# WKUP_CTRL_MMR0_CFG0 register map
Vendor: Texas Instruments
Peripheral module from a debugger description file (folder am62A).
Registers are 32-bit, read-write, reset 0x0 unless marked. A register's access mark holds for its fields unless they carry their own. Offsets are as the file gives them; lines under a group give offsets from that group; [hi:lo] are bit positions; {n}, {i} and the like mark numbered series; 'fields as' and 'values as' point back to an identical list; <NAME> marks a mode.

## WKUP_CTRL_MMR0_CFG0 (part 1 of 2)
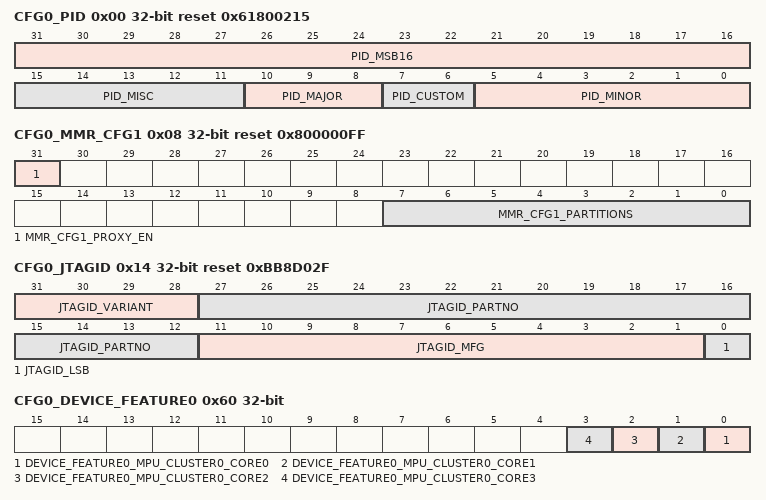
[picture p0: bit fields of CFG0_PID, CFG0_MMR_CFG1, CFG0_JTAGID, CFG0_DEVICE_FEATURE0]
0x00 CFG0_PID ro reset 0x61800215
  [31:16] PID_MSB16, [15:11] PID_MISC, [10:8] PID_MAJOR, [7:6] PID_CUSTOM, [5:0] PID_MINOR
0x08 CFG0_MMR_CFG1 ro reset 0x800000FF
  [31] MMR_CFG1_PROXY_EN — Proxy addressing activated
  [7:0] MMR_CFG1_PARTITIONS — Indicates present partitions
0x14 CFG0_JTAGID ro reset 0xBB8D02F
  [31:28] JTAGID_VARIANT — Used to indicate new PGs
  [27:12] JTAGID_PARTNO — Part number for boundary scan
  [11:1] JTAGID_MFG — Indicates manufacturer
  [0] JTAGID_LSB — Always 1
0x18 CFG0_JTAG_USER_ID ro
  [31:0] JTAG_USER_ID_USERCODE — Device information
0x30 CFG0_MAIN_DEVSTAT
  [15:0] MAIN_DEVSTAT_BOOTMODE — Specifies the device Primary and Backup boot media.
0x34 CFG0_MAIN_BOOTCFG ro
  [15:0] MAIN_BOOTCFG_BOOTMODE — Specifies the device Primary and Backup boot media as latched at PORz
0x44 CFG0_BOOT_PROGRESS
  [31:0] BOOT_PROGRESS_PROGRESS — Written by ROM to indicate boot progression. Values and their meaning are determined by the ROM.
0x60 CFG0_DEVICE_FEATURE0 ro
  [n] DEVICE_FEATURE0_MPU_CLUSTER0_CORE{n} (n=0..3) — MPU Cluster0 Core {n} is activated when set
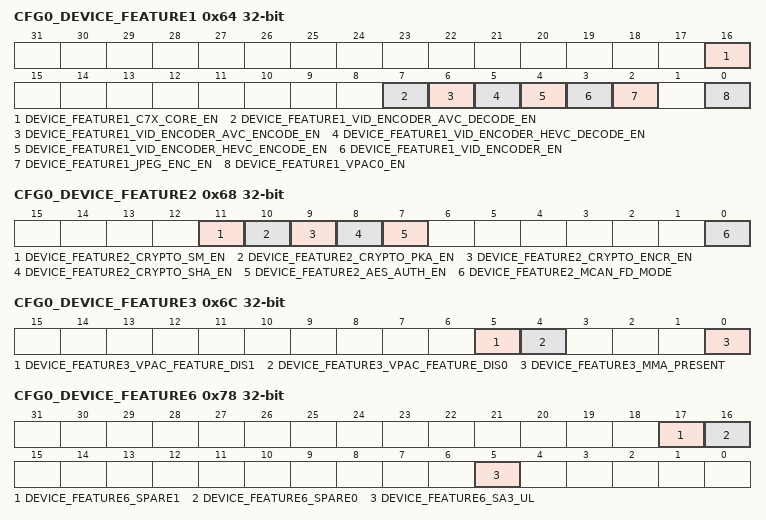
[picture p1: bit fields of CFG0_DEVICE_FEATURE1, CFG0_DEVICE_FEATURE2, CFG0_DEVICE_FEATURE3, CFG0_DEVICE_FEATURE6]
0x64 CFG0_DEVICE_FEATURE1 ro
  [16] DEVICE_FEATURE1_C7X_CORE_EN — C7x is activated when set
  [7] DEVICE_FEATURE1_VID_ENCODER_AVC_DECODE_EN — Video CODEC HEVC decode feature activated when set
  [6] DEVICE_FEATURE1_VID_ENCODER_AVC_ENCODE_EN — Video CODEC HEVC encode feature activated when set
  [5] DEVICE_FEATURE1_VID_ENCODER_HEVC_DECODE_EN — Video CODEC AVC decode feature activated when set
  [4] DEVICE_FEATURE1_VID_ENCODER_HEVC_ENCODE_EN — Video CODEC AVC encode feature activated when set
  [3] DEVICE_FEATURE1_VID_ENCODER_EN — Video CODEC is activated when set
  [2] DEVICE_FEATURE1_JPEG_ENC_EN — JPEG Encoder is activated when set
  [0] DEVICE_FEATURE1_VPAC0_EN — VPAC0 is activated when set
0x68 CFG0_DEVICE_FEATURE2 ro
  [11] DEVICE_FEATURE2_CRYPTO_SM_EN — SA3SS Crypto Module SM2, SM3, SM4 activated
  [10] DEVICE_FEATURE2_CRYPTO_PKA_EN — SA3SS Crypto Module PKA activated
  [9] DEVICE_FEATURE2_CRYPTO_ENCR_EN — SA3SS Crypto Module AES/3DES/DBRG activated
  [8] DEVICE_FEATURE2_CRYPTO_SHA_EN — SA3SS Crypto Module SHA/MD5 activated
  [7] DEVICE_FEATURE2_AES_AUTH_EN — AES authentication is activated in FlashSS and SMS when set
  [0] DEVICE_FEATURE2_MCAN_FD_MODE — FD mode is supported on all MCAN when set
0x6C CFG0_DEVICE_FEATURE3 ro
  [5] DEVICE_FEATURE3_VPAC_FEATURE_DIS1 — VPAC Feature 1 Deactivated When Set
  [4] DEVICE_FEATURE3_VPAC_FEATURE_DIS0 — VPAC Feature 0 DIsabled When Set
  [0] DEVICE_FEATURE3_MMA_PRESENT — C7x MMA Present when Set
0x78 CFG0_DEVICE_FEATURE6 ro
  [17] DEVICE_FEATURE6_SPARE1 — Spare1 LPSC is activated when set
  [16] DEVICE_FEATURE6_SPARE0 — Spare0 LPSC is activated when set
  [5] DEVICE_FEATURE6_SA3_UL — SA3SS domain security accelerator is activated when set
0x200 CFG0_MAC_ID0
  [31:0] MAC_ID0_MACID_LO — 32 lsbs of MAC address
0x204 CFG0_MAC_ID1
  [15:0] MAC_ID1_MACID_HI — 16 msbs of MAC address
0x220 CFG0_USB_DEVICE_ID0 reset 0x61650451
  [31:0] USB_DEVICE_ID0_ID0 — ROM writes 32-bit Value from Customer OTP to Here
0x224 CFG0_USB_DEVICE_ID1 reset 0x61650451
  [31:0] USB_DEVICE_ID1_ID1 — ROM writes 32-bit Value from Customer OTP to Here
{0x230+4i} CFG0_GP_SW{i} ro (i=0..2)
  [31:0] GP_SW{i}_VAL — general purpose value
0x23C CFG0_GP_SW3 ro
  [3:0] GP_SW3_VAL — general purpose value
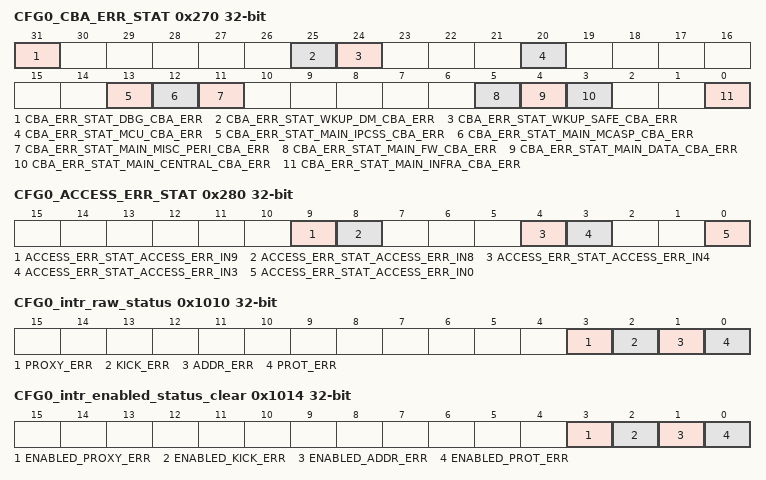
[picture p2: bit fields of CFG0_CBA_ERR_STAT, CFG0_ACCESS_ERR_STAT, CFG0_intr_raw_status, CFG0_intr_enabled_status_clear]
0x270 CFG0_CBA_ERR_STAT ro
  [31] CBA_ERR_STAT_DBG_CBA_ERR — Access Error from Main Debug CBASS
  [25] CBA_ERR_STAT_WKUP_DM_CBA_ERR — Access Error from Wkup Device Manager CBASS
  [24] CBA_ERR_STAT_WKUP_SAFE_CBA_ERR — Access Error from Wkup Safe CBASS
  [20] CBA_ERR_STAT_MCU_CBA_ERR — Access Error from MCU CBASS
  [13] CBA_ERR_STAT_MAIN_IPCSS_CBA_ERR — Access Error from Main IPCSS CBASS
  [12] CBA_ERR_STAT_MAIN_MCASP_CBA_ERR — Access Error from Main McASP CBASS
  [11] CBA_ERR_STAT_MAIN_MISC_PERI_CBA_ERR — Access Errror from Main Misc. Peripheral CBASS
  [5] CBA_ERR_STAT_MAIN_FW_CBA_ERR — Access Error from Main Firewall CBASS
  [4] CBA_ERR_STAT_MAIN_DATA_CBA_ERR — Access Error from Main Data CBASS
  [3] CBA_ERR_STAT_MAIN_CENTRAL_CBA_ERR — Access Error from Main Central CBASS
  [0] CBA_ERR_STAT_MAIN_INFRA_CBA_ERR — Access Error from Main Infrastructure CBASS
0x280 CFG0_ACCESS_ERR_STAT ro
  [9] ACCESS_ERR_STAT_ACCESS_ERR_IN9 — Access Error Detected in MCU PadCfg MMR
  [8] ACCESS_ERR_STAT_ACCESS_ERR_IN8 — Access Error Detected in MCU Ctrl MMR
  [4] ACCESS_ERR_STAT_ACCESS_ERR_IN4 — Access Error Detected in MAIN PadCfg MMR
  [3] ACCESS_ERR_STAT_ACCESS_ERR_IN3 — Access Error Detected in MAIN Ctrl MMR
  [0] ACCESS_ERR_STAT_ACCESS_ERR_IN0 — Access Error Detected in WKUP Ctrl MMR
{0x1008+0x4000*i} CFG0_LOCK{i}_KICK0 (i=0..7)
  [31:0] LOCK{i}_KICK0 — - KICK0 component
{0x100C+0x4000*i} CFG0_LOCK{i}_KICK1 (i=0..7)
  [31:0] LOCK{i}_KICK1 — - KICK1 component
0x1010 CFG0_intr_raw_status access not given
  [3] PROXY_ERR — Proxy0 access violation error. Raw status is read. Write a 1 to set the status. Writing a 0 has no effect. (access R/W1TS)
  [2] KICK_ERR — Kick access violation error. Raw status is read. Write a 1 to set the status. Writing a 0 has no effect. (access R/W1TS)
  [1] ADDR_ERR — Addressing violation error. Raw status is read. Write a 1 to set the status. Writing a 0 has no effect. (access R/W1TS)
  [0] PROT_ERR — Protection violation error. Raw status is read. Write a 1 to set the status. Writing a 0 has no effect. (access R/W1TS)
0x1014 CFG0_intr_enabled_status_clear access not given
  [3] ENABLED_PROXY_ERR — Proxy0 access violation error. Enabled status is read. Write a 1 to clear the status. Writing a 0 has no effect. (access R/W1TC)
  [2] ENABLED_KICK_ERR — Kick access violation error. Enabled status is read. Write a 1 to clear the status. Writing a 0 has no effect. (access R/W1TC)
  [1] ENABLED_ADDR_ERR — Addressing violation error. Enabled status is read. Write a 1 to clear the status. Writing a 0 has no effect. (access R/W1TC)
  [0] ENABLED_PROT_ERR — Protection violation error. Enabled status is read. Write a 1 to clear the status. Writing a 0 has no effect. (access R/W1TC)
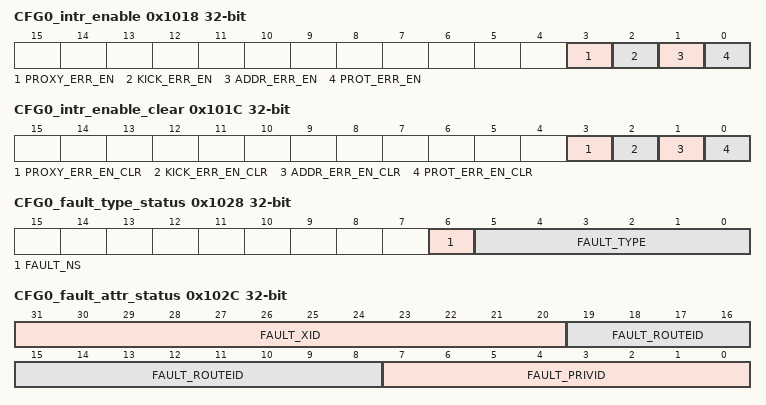
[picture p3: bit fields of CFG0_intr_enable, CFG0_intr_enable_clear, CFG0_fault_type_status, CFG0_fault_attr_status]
0x1018 CFG0_intr_enable access not given
  [3] PROXY_ERR_EN — Proxy0 access violation error enable. Write a 1 to set the enable. Writing a 0 has no effect. (access R/W1TS)
  [2] KICK_ERR_EN — Kick access violation error enable. Write a 1 to set the enable. Writing a 0 has no effect. (access R/W1TS)
  [1] ADDR_ERR_EN — Addressing violation error enable. Write a 1 to set the enable. Writing a 0 has no effect. (access R/W1TS)
  [0] PROT_ERR_EN — Protection violation error enable. Write a 1 to set the enable. Writing a 0 has no effect. (access R/W1TS)
0x101C CFG0_intr_enable_clear access not given
  [3] PROXY_ERR_EN_CLR — Proxy0 access violation error enable clear. Write a 1 to clear the enable. Writing a 0 has no effect. (access R/W1TC)
  [2] KICK_ERR_EN_CLR — Kick access violation error enable clear. Write a 1 to clear the enable. Writing a 0 has no effect. (access R/W1TC)
  [1] ADDR_ERR_EN_CLR — Addressing violation error enable clear. Write a 1 to clear the enable. Writing a 0 has no effect. (access R/W1TC)
  [0] PROT_ERR_EN_CLR — Protection violation error enable clear. Write a 1 to clear the enable. Writing a 0 has no effect. (access R/W1TC)
0x1020 CFG0_eoi
  [7:0] EOI_VECTOR — EOI vector value. Write this with interrupt distribution value in the chip.
0x1024 CFG0_fault_address ro
  [31:0] FAULT_ADDR — Fault Address.
0x1028 CFG0_fault_type_status ro
  [6] FAULT_NS — Non-secure access.
  [5:0] FAULT_TYPE — Fault Type 10_0000 = Supervisor read fault - priv = 1 dir = 1 dtype != 1 01_0000 = Supervisor write fault - priv = 1 dir = 0 00_1000 = Supervisor execute fault - priv = 1 dir = 1 dtype = 1 00_0100 = User read fault - priv = 0 dir = 1 dtype = 1 00_0010 = User write fault - priv = 0 dir = 0 00_0001 = User execute fault - priv = 0 dir = 1 dtype = 1 00_0000 = No fault
0x102C CFG0_fault_attr_status ro
  [31:20] FAULT_XID — XID.
  [19:8] FAULT_ROUTEID — Route ID.
  [7:0] FAULT_PRIVID — Privilege ID.
0x1030 CFG0_fault_clear wo
  [0] FAULT_CLR — Fault clear. Writing a 1 clears the current fault. Writing a 0 has no effect.
{0x1100+4i} CFG0_CLAIMREG_P0_R{i}_READONLY ro (i=0..6)
  [31:0] CLAIMREG_P0_R{i}_READONLY — Claim bits for Partition 0
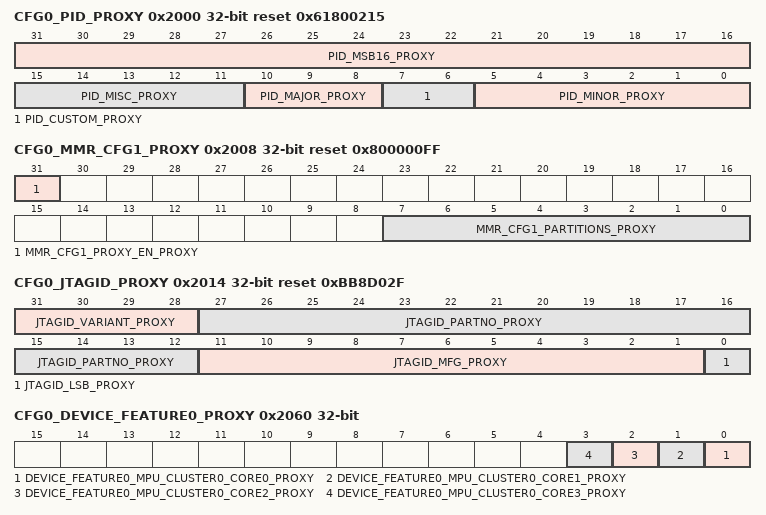
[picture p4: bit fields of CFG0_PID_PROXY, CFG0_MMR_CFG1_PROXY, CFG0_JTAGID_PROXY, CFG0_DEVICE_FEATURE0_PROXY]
0x2000 CFG0_PID_PROXY ro reset 0x61800215
  [31:16] PID_MSB16_PROXY, [15:11] PID_MISC_PROXY, [10:8] PID_MAJOR_PROXY, [7:6] PID_CUSTOM_PROXY, [5:0] PID_MINOR_PROXY
0x2008 CFG0_MMR_CFG1_PROXY ro reset 0x800000FF
  [31] MMR_CFG1_PROXY_EN_PROXY — Proxy addressing activated
  [7:0] MMR_CFG1_PARTITIONS_PROXY — Indicates present partitions
0x2014 CFG0_JTAGID_PROXY ro reset 0xBB8D02F
  [31:28] JTAGID_VARIANT_PROXY — Used to indicate new PGs
  [27:12] JTAGID_PARTNO_PROXY — Part number for boundary scan
  [11:1] JTAGID_MFG_PROXY — Indicates manufacturer
  [0] JTAGID_LSB_PROXY — Always 1
0x2018 CFG0_JTAG_USER_ID_PROXY ro
  [31:0] JTAG_USER_ID_USERCODE_PROXY — Device information
0x2030 CFG0_MAIN_DEVSTAT_PROXY
  [15:0] MAIN_DEVSTAT_BOOTMODE_PROXY — Specifies the device Primary and Backup boot media.
0x2034 CFG0_MAIN_BOOTCFG_PROXY ro
  [15:0] MAIN_BOOTCFG_BOOTMODE_PROXY — Specifies the device Primary and Backup boot media as latched at PORz
0x2044 CFG0_BOOT_PROGRESS_PROXY
  [31:0] BOOT_PROGRESS_PROGRESS_PROXY — Written by ROM to indicate boot progression. Values and their meaning are determined by the ROM.
0x2060 CFG0_DEVICE_FEATURE0_PROXY ro
  [n] DEVICE_FEATURE0_MPU_CLUSTER0_CORE{n}_PROXY (n=0..3) — MPU Cluster0 Core {n} is activated when set
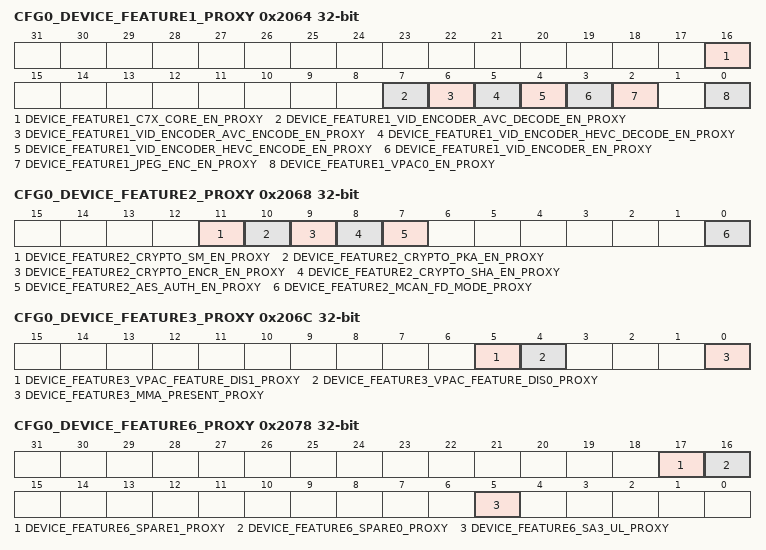
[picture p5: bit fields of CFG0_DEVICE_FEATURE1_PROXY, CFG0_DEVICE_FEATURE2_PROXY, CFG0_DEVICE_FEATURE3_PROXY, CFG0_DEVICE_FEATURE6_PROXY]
0x2064 CFG0_DEVICE_FEATURE1_PROXY ro
  [16] DEVICE_FEATURE1_C7X_CORE_EN_PROXY — C7x is activated when set
  [7] DEVICE_FEATURE1_VID_ENCODER_AVC_DECODE_EN_PROXY — Video CODEC HEVC decode feature activated when set
  [6] DEVICE_FEATURE1_VID_ENCODER_AVC_ENCODE_EN_PROXY — Video CODEC HEVC encode feature activated when set
  [5] DEVICE_FEATURE1_VID_ENCODER_HEVC_DECODE_EN_PROXY — Video CODEC AVC decode feature activated when set
  [4] DEVICE_FEATURE1_VID_ENCODER_HEVC_ENCODE_EN_PROXY — Video CODEC AVC encode feature activated when set
  [3] DEVICE_FEATURE1_VID_ENCODER_EN_PROXY — Video CODEC is activated when set
  [2] DEVICE_FEATURE1_JPEG_ENC_EN_PROXY — JPEG Encoder is activated when set
  [0] DEVICE_FEATURE1_VPAC0_EN_PROXY — VPAC0 is activated when set
0x2068 CFG0_DEVICE_FEATURE2_PROXY ro
  [11] DEVICE_FEATURE2_CRYPTO_SM_EN_PROXY — SA3SS Crypto Module SM2, SM3, SM4 activated
  [10] DEVICE_FEATURE2_CRYPTO_PKA_EN_PROXY — SA3SS Crypto Module PKA activated
  [9] DEVICE_FEATURE2_CRYPTO_ENCR_EN_PROXY — SA3SS Crypto Module AES/3DES/DBRG activated
  [8] DEVICE_FEATURE2_CRYPTO_SHA_EN_PROXY — SA3SS Crypto Module SHA/MD5 activated
  [7] DEVICE_FEATURE2_AES_AUTH_EN_PROXY — AES authentication is activated in FlashSS and SMS when set
  [0] DEVICE_FEATURE2_MCAN_FD_MODE_PROXY — FD mode is supported on all MCAN when set
0x206C CFG0_DEVICE_FEATURE3_PROXY ro
  [5] DEVICE_FEATURE3_VPAC_FEATURE_DIS1_PROXY — VPAC Feature 1 Deactivated When Set
  [4] DEVICE_FEATURE3_VPAC_FEATURE_DIS0_PROXY — VPAC Feature 0 DIsabled When Set
  [0] DEVICE_FEATURE3_MMA_PRESENT_PROXY — C7x MMA Present when Set
0x2078 CFG0_DEVICE_FEATURE6_PROXY ro
  [17] DEVICE_FEATURE6_SPARE1_PROXY — Spare1 LPSC is activated when set
  [16] DEVICE_FEATURE6_SPARE0_PROXY — Spare0 LPSC is activated when set
  [5] DEVICE_FEATURE6_SA3_UL_PROXY — SA3SS domain security accelerator is activated when set
0x2200 CFG0_MAC_ID0_PROXY
  [31:0] MAC_ID0_MACID_LO_PROXY — 32 lsbs of MAC address
0x2204 CFG0_MAC_ID1_PROXY
  [15:0] MAC_ID1_MACID_HI_PROXY — 16 msbs of MAC address
0x2220 CFG0_USB_DEVICE_ID0_PROXY reset 0x61650451
  [31:0] USB_DEVICE_ID0_ID0_PROXY — ROM writes 32-bit Value from Customer OTP to Here
0x2224 CFG0_USB_DEVICE_ID1_PROXY reset 0x61650451
  [31:0] USB_DEVICE_ID1_ID1_PROXY — ROM writes 32-bit Value from Customer OTP to Here
{0x2230+4i} CFG0_GP_SW{i}_PROXY ro (i=0..2)
  [31:0] GP_SW{i}_VAL_PROXY — general purpose value
0x223C CFG0_GP_SW3_PROXY ro
  [3:0] GP_SW3_VAL_PROXY — general purpose value
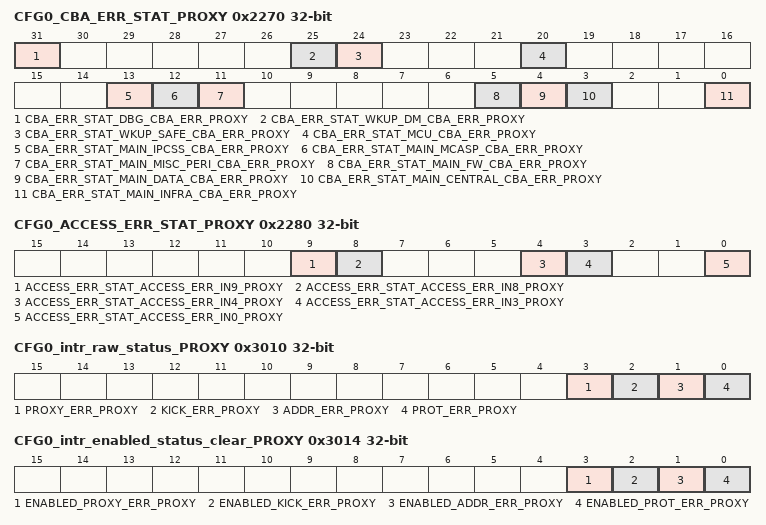
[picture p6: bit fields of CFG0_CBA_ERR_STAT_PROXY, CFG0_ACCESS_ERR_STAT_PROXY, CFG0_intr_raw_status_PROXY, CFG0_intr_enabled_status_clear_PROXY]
0x2270 CFG0_CBA_ERR_STAT_PROXY ro
  [31] CBA_ERR_STAT_DBG_CBA_ERR_PROXY — Access Error from Main Debug CBASS
  [25] CBA_ERR_STAT_WKUP_DM_CBA_ERR_PROXY — Access Error from Wkup Device Manager CBASS
  [24] CBA_ERR_STAT_WKUP_SAFE_CBA_ERR_PROXY — Access Error from Wkup Safe CBASS
  [20] CBA_ERR_STAT_MCU_CBA_ERR_PROXY — Access Error from MCU CBASS
  [13] CBA_ERR_STAT_MAIN_IPCSS_CBA_ERR_PROXY — Access Error from Main IPCSS CBASS
  [12] CBA_ERR_STAT_MAIN_MCASP_CBA_ERR_PROXY — Access Error from Main McASP CBASS
  [11] CBA_ERR_STAT_MAIN_MISC_PERI_CBA_ERR_PROXY — Access Errror from Main Misc. Peripheral CBASS
  [5] CBA_ERR_STAT_MAIN_FW_CBA_ERR_PROXY — Access Error from Main Firewall CBASS
  [4] CBA_ERR_STAT_MAIN_DATA_CBA_ERR_PROXY — Access Error from Main Data CBASS
  [3] CBA_ERR_STAT_MAIN_CENTRAL_CBA_ERR_PROXY — Access Error from Main Central CBASS
  [0] CBA_ERR_STAT_MAIN_INFRA_CBA_ERR_PROXY — Access Error from Main Infrastructure CBASS
0x2280 CFG0_ACCESS_ERR_STAT_PROXY ro
  [9] ACCESS_ERR_STAT_ACCESS_ERR_IN9_PROXY — Access Error Detected in MCU PadCfg MMR
  [8] ACCESS_ERR_STAT_ACCESS_ERR_IN8_PROXY — Access Error Detected in MCU Ctrl MMR
  [4] ACCESS_ERR_STAT_ACCESS_ERR_IN4_PROXY — Access Error Detected in MAIN PadCfg MMR
  [3] ACCESS_ERR_STAT_ACCESS_ERR_IN3_PROXY — Access Error Detected in MAIN Ctrl MMR
  [0] ACCESS_ERR_STAT_ACCESS_ERR_IN0_PROXY — Access Error Detected in WKUP Ctrl MMR
{0x3008+0x4000*i} CFG0_LOCK{i}_KICK0_PROXY (i=0..7)
  [31:0] LOCK{i}_KICK0_PROXY — - KICK0 component
{0x300C+0x4000*i} CFG0_LOCK{i}_KICK1_PROXY (i=0..7)
  [31:0] LOCK{i}_KICK1_PROXY — - KICK1 component
0x3010 CFG0_intr_raw_status_PROXY access not given
  [3] PROXY_ERR_PROXY — Proxy0 access violation error. Raw status is read. Write a 1 to set the status. Writing a 0 has no effect. (access R/W1TS)
  [2] KICK_ERR_PROXY — Kick access violation error. Raw status is read. Write a 1 to set the status. Writing a 0 has no effect. (access R/W1TS)
  [1] ADDR_ERR_PROXY — Addressing violation error. Raw status is read. Write a 1 to set the status. Writing a 0 has no effect. (access R/W1TS)
  [0] PROT_ERR_PROXY — Protection violation error. Raw status is read. Write a 1 to set the status. Writing a 0 has no effect. (access R/W1TS)
0x3014 CFG0_intr_enabled_status_clear_PROXY access not given
  [3] ENABLED_PROXY_ERR_PROXY — Proxy0 access violation error. Enabled status is read. Write a 1 to clear the status. Writing a 0 has no effect. (access R/W1TC)
  [2] ENABLED_KICK_ERR_PROXY — Kick access violation error. Enabled status is read. Write a 1 to clear the status. Writing a 0 has no effect. (access R/W1TC)
  [1] ENABLED_ADDR_ERR_PROXY — Addressing violation error. Enabled status is read. Write a 1 to clear the status. Writing a 0 has no effect. (access R/W1TC)
  [0] ENABLED_PROT_ERR_PROXY — Protection violation error. Enabled status is read. Write a 1 to clear the status. Writing a 0 has no effect. (access R/W1TC)
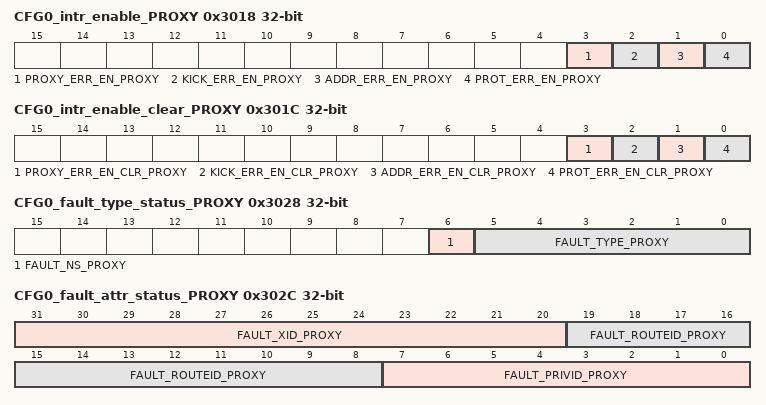
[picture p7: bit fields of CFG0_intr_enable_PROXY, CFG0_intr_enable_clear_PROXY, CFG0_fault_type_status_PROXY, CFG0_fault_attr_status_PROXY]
0x3018 CFG0_intr_enable_PROXY access not given
  [3] PROXY_ERR_EN_PROXY — Proxy0 access violation error enable. Write a 1 to set the enable. Writing a 0 has no effect. (access R/W1TS)
  [2] KICK_ERR_EN_PROXY — Kick access violation error enable. Write a 1 to set the enable. Writing a 0 has no effect. (access R/W1TS)
  [1] ADDR_ERR_EN_PROXY — Addressing violation error enable. Write a 1 to set the enable. Writing a 0 has no effect. (access R/W1TS)
  [0] PROT_ERR_EN_PROXY — Protection violation error enable. Write a 1 to set the enable. Writing a 0 has no effect. (access R/W1TS)
0x301C CFG0_intr_enable_clear_PROXY access not given
  [3] PROXY_ERR_EN_CLR_PROXY — Proxy0 access violation error enable clear. Write a 1 to clear the enable. Writing a 0 has no effect. (access R/W1TC)
  [2] KICK_ERR_EN_CLR_PROXY — Kick access violation error enable clear. Write a 1 to clear the enable. Writing a 0 has no effect. (access R/W1TC)
  [1] ADDR_ERR_EN_CLR_PROXY — Addressing violation error enable clear. Write a 1 to clear the enable. Writing a 0 has no effect. (access R/W1TC)
  [0] PROT_ERR_EN_CLR_PROXY — Protection violation error enable clear. Write a 1 to clear the enable. Writing a 0 has no effect. (access R/W1TC)
0x3020 CFG0_eoi_PROXY
  [7:0] EOI_VECTOR_PROXY — EOI vector value. Write this with interrupt distribution value in the chip.
0x3024 CFG0_fault_address_PROXY ro
  [31:0] FAULT_ADDR_PROXY — Fault Address.
0x3028 CFG0_fault_type_status_PROXY ro
  [6] FAULT_NS_PROXY — Non-secure access.
  [5:0] FAULT_TYPE_PROXY — Fault Type 10_0000 = Supervisor read fault - priv = 1 dir = 1 dtype != 1 01_0000 = Supervisor write fault - priv = 1 dir = 0 00_1000 = Supervisor execute fault - priv = 1 dir = 1 dtype = 1 00_0100 = User read fault - priv = 0 dir = 1 dtype = 1 00_0010 = User write fault - priv = 0 dir = 0 00_0001 = User execute fault - priv = 0 dir = 1 dtype = 1 00_0000 = No fault
0x302C CFG0_fault_attr_status_PROXY ro
  [31:20] FAULT_XID_PROXY — XID.
  [19:8] FAULT_ROUTEID_PROXY — Route ID.
  [7:0] FAULT_PRIVID_PROXY — Privilege ID.
0x3030 CFG0_fault_clear_PROXY wo
  [0] FAULT_CLR_PROXY — Fault clear. Writing a 1 clears the current fault. Writing a 0 has no effect.
{0x3100+4i} CFG0_CLAIMREG_P0_R{i} (i=0..6)
  [31:0] CLAIMREG_P0_R{i} — Claim bits for Partition 0
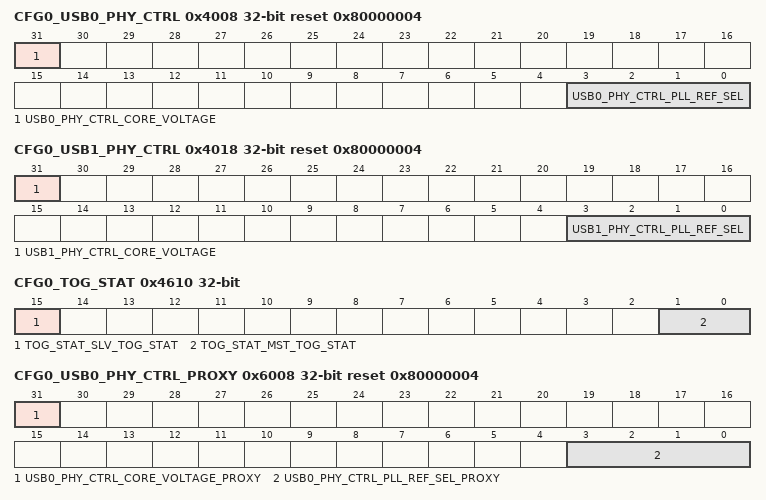
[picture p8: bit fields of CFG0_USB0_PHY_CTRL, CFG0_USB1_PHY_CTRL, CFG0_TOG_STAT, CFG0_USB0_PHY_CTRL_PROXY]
0x4008 CFG0_USB0_PHY_CTRL reset 0x80000004
  [31] USB0_PHY_CTRL_CORE_VOLTAGE — Selects the USB PHY Core Voltage 0 - Core Voltage is 0.85V 1 - Core Voltage is 0.75V/0.80V
  [3:0] USB0_PHY_CTRL_PLL_REF_SEL — Indicates the frequency of the REF_CLOCK input used by the USB PLL. This value should be set to match the frequency of the USB0 input clock, as selected by the USB0_CLKSEL register Field values (others are reserved): 4'b0000 - 9.6 MHz 4'b0001 - 10 MHz 4'b0010 - 12 MHz 4'b0011 - 19.2 MHZ 4'b0100 - 20 MHz 4'b0101 - 24 MHz 4'b0110 - 25 MHz 4'b0111 - 26 MHz 4'b1000 - 38.4 MHz 4'b1001 - 40 MHz 4'b1010 - 48 MHz 4'b1011 - 50 MHz 4'b1100 - 52 MHz
0x4018 CFG0_USB1_PHY_CTRL reset 0x80000004
  [31] USB1_PHY_CTRL_CORE_VOLTAGE — Selects the USB PHY Core Voltage 0 - Core Voltage is 0.85V 1 - Core Voltage is 0.75V/0.80V
  [3:0] USB1_PHY_CTRL_PLL_REF_SEL — Indicates the frequency of the REF_CLOCK input used by the USB PLL. This value should be set to match the frequency of the USB1 input clock, as selected by the USB1_CLKSEL register Field values (others are reserved): 4'b0000 - 9.6 MHz 4'b0001 - 10 MHz 4'b0010 - 12 MHz 4'b0011 - 19.2 MHZ 4'b0100 - 20 MHz 4'b0101 - 24 MHz 4'b0110 - 25 MHz 4'b0111 - 26 MHz 4'b1000 - 38.4 MHz 4'b1001 - 40 MHz 4'b1010 - 48 MHz 4'b1011 - 50 MHz 4'b1100 - 52 MHz
{0x41B4+4i} CFG0_SDIO{i}_CTRL (i=0..2)
  [4:0] SDIO{i}_CTRL_DRV_STR — Selects the SDIO drive strength
0x4204 CFG0_WKUP_TIMER1_CTRL
  [8] WKUP_TIMER1_CTRL_CASCADE_EN — Activates cascading of TIMER1 to TIMER0
0x42E0 CFG0_WKUP_I2C0_CTRL
  [0] WKUP_I2C0_CTRL_HS_MCS_EN — HS Mode controller current source activate. When set, activates the current-source pull-up on the SCL output. Only one controller on the I2C bus should activate SCL current sourcing.
0x4610 CFG0_TOG_STAT ro
  [15] TOG_STAT_SLV_TOG_STAT — Error Status of Target Timeout Gaskets Field values (others are reserved): 1'b0 - No Error 1'b1 - Error from mcu2dm timeout gasket MCU_TIMEOUT0
  [1:0] TOG_STAT_MST_TOG_STAT — Error Status of Target Timeout Gaskets Field values (others are reserved): 2'b00 - No Error 2'b01 - Error from dm2mcu WKUP_TIMEOUT1 gasket 2'b10 - Error from dm2ws WKUP_TIMEOUT0 gasket 2'b11 - Error from both dm2mcu and dm2ws WKUP_TIMEOUT1 and WKUP_TIMEOUT0 gaskets
{0x5100+4i} CFG0_CLAIMREG_P1_R{i}_READONLY ro (i=0..12)
  [31:0] CLAIMREG_P1_R{i}_READONLY — Claim bits for Partition 1
0x6008 CFG0_USB0_PHY_CTRL_PROXY reset 0x80000004
  [31] USB0_PHY_CTRL_CORE_VOLTAGE_PROXY — Selects the USB PHY Core Voltage 0 - Core Voltage is 0.85V 1 - Core Voltage is 0.75V/0.80V
  [3:0] USB0_PHY_CTRL_PLL_REF_SEL_PROXY — Indicates the frequency of the REF_CLOCK input used by the USB PLL. This value should be set to match the frequency of the USB0 input clock, as selected by the USB0_CLKSEL register Field values (others are reserved): 4'b0000 - 9.6 MHz 4'b0001 - 10 MHz 4'b0010 - 12 MHz 4'b0011 - 19.2 MHZ 4'b0100 - 20 MHz 4'b0101 - 24 MHz 4'b0110 - 25 MHz 4'b0111 - 26 MHz 4'b1000 - 38.4 MHz 4'b1001 - 40 MHz 4'b1010 - 48 MHz 4'b1011 - 50 MHz 4'b1100 - 52 MHz
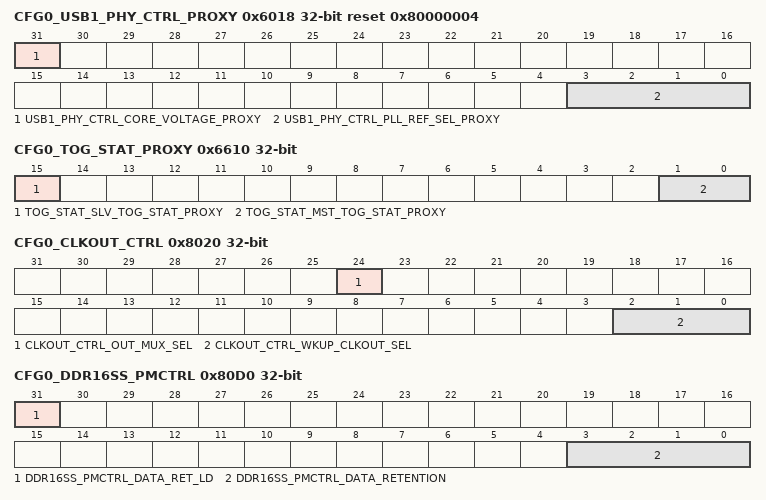
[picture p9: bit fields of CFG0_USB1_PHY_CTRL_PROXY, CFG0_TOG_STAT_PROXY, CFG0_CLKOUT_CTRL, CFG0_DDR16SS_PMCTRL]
0x6018 CFG0_USB1_PHY_CTRL_PROXY reset 0x80000004
  [31] USB1_PHY_CTRL_CORE_VOLTAGE_PROXY — Selects the USB PHY Core Voltage 0 - Core Voltage is 0.85V 1 - Core Voltage is 0.75V/0.80V
  [3:0] USB1_PHY_CTRL_PLL_REF_SEL_PROXY — Indicates the frequency of the REF_CLOCK input used by the USB PLL. This value should be set to match the frequency of the USB1 input clock, as selected by the USB1_CLKSEL register Field values (others are reserved): 4'b0000 - 9.6 MHz 4'b0001 - 10 MHz 4'b0010 - 12 MHz 4'b0011 - 19.2 MHZ 4'b0100 - 20 MHz 4'b0101 - 24 MHz 4'b0110 - 25 MHz 4'b0111 - 26 MHz 4'b1000 - 38.4 MHz 4'b1001 - 40 MHz 4'b1010 - 48 MHz 4'b1011 - 50 MHz 4'b1100 - 52 MHz
{0x61B4+4i} CFG0_SDIO{i}_CTRL_PROXY (i=0..2)
  [4:0] SDIO{i}_CTRL_DRV_STR_PROXY — Selects the SDIO drive strength
0x6204 CFG0_WKUP_TIMER1_CTRL_PROXY
  [8] WKUP_TIMER1_CTRL_CASCADE_EN_PROXY — Activates cascading of TIMER1 to TIMER0
0x62E0 CFG0_WKUP_I2C0_CTRL_PROXY
  [0] WKUP_I2C0_CTRL_HS_MCS_EN_PROXY — HS Mode controller current source activate. When set, activates the current-source pull-up on the SCL output. Only one controller on the I2C bus should activate SCL current sourcing.
0x6610 CFG0_TOG_STAT_PROXY ro
  [15] TOG_STAT_SLV_TOG_STAT_PROXY — Error Status of Target Timeout Gaskets Field values (others are reserved): 1'b0 - No Error 1'b1 - Error from mcu2dm timeout gasket MCU_TIMEOUT0
  [1:0] TOG_STAT_MST_TOG_STAT_PROXY — Error Status of Target Timeout Gaskets Field values (others are reserved): 2'b00 - No Error 2'b01 - Error from dm2mcu WKUP_TIMEOUT1 gasket 2'b10 - Error from dm2ws WKUP_TIMEOUT0 gasket 2'b11 - Error from both dm2mcu and dm2ws WKUP_TIMEOUT1 and WKUP_TIMEOUT0 gaskets
{0x7100+4i} CFG0_CLAIMREG_P1_R{i} (i=0..12)
  [31:0] CLAIMREG_P1_R{i} — Claim bits for Partition 1
0x8010 CFG0_WKUP_CLKSEL
  [0] WKUP_CLKSEL_CLK_SEL — Selects Clock Source for Wakeup Domain (Device Manager and Peripherals) Field values (others are reserved): 1'b0 - CPU: MAIN_PLL15_HSDIV2_CLKOUT, Peripherals: MAIN_PLL15_HSDIV0_CLKOUT0 1'b1 - CPU and Peripherals: MCU_PLL0_HSDIV0_CKLOUT
0x8020 CFG0_CLKOUT_CTRL
  [24] CLKOUT_CTRL_OUT_MUX_SEL — WKUP CLKOUT pin output mux selection. Note, when HFOSC0_CLK is selected (1'b1) the CLKOUT_CTRL_wkup_clkout_sel field must be programmed to 4'b0001. 1'b0 - The output of the WKUP CLKOUT output divider is output on the pin 1'b1 - HFOSC0_CLK is output on the pin
  [2:0] CLKOUT_CTRL_WKUP_CLKOUT_SEL — Controls WKUP CLKOUT MUX for WKUP_CLKOUT0 Pin Field values (others are reserved): undefined - undefined 3'b000 - HFOSC0_CLKOUT 3'b001 - LFOSC0_CLKOUT 3'b010 - MAIN_PLL0_HSDIV2_CLKOUT 3'b011 - MAIN_PLL1_HSDIV2_CLKOUT 3'b100 - MAIN_PLL2_HSDIV9_CLKOUT 3'b101 - DEVICE_CLKOUT_32K 3'b110 - CLK_12M_RC 3'b111 - HFOSC0_CLKOUT
0x8030 CFG0_WKUP_GTC_CLKSEL reset 0x1
  [2:0] WKUP_GTC_CLKSEL_CLK_SEL — Selects the GTC timebase clock source Field values (others are reserved): 3'b000 - MAIN_PLL2_HSDIV5_CLKOUT 3'b001 - MAIN_PLL0_HSDIV6_CLKOUT 3'b010 - CPSW2G_CPTS_RFT_CLK 3'b011 - Reserved '0' 3'b100 - MCU_EXT_REFCLK0 3'b101 - EXT_REFCLK1 3'b110 - MCU_SYSCLK0 undefined - undefined 3'b111 - MAIN_SYSCLK0
0x803C CFG0_EFUSE_CLKSEL
  [0] EFUSE_CLKSEL_CLK_SEL — Selects the clock source Field values (others are reserved): 1'b0 - HFOSC0_CLKOUT 1'b1 - MAIN_SYSCLK0/16
0x80D0 CFG0_DDR16SS_PMCTRL
  [31] DDR16SS_PMCTRL_DATA_RET_LD — Controls latching of the retention value Field values (others are reserved): 1'b0 - Latch Closed 1'b1 - Latch Open
  [3:0] DDR16SS_PMCTRL_DATA_RETENTION — DDR16SS Retention: This is a fault tolerant bit field 0x06 Asserts DDRSS 'data_retention' which will Hi-Z most of the phy output pins except for CKE/RESET# All others (Default 0) : data_retention is deasserted for normal DDR16SS Operation Field values (others are reserved): 4'b0110 - Retention Activated 4'b0000 - Retention Deactivated
0x8190 CFG0_USB0_CLKSEL
  [0] USB0_CLKSEL_REFCLK_SEL — Selects the clock source for the USB0 ref_clk. Field values (others are reserved): 1'b0 - HFOSC0_CLKOUT 1'b1 - MAIN_PLL0_HSDIV8_CLKOUT
0x8194 CFG0_USB1_CLKSEL
  [0] USB1_CLKSEL_REFCLK_SEL — Selects the clock source for the USB1 ref_clk. Field values (others are reserved): 1'b0 - HFOSC0_CLKOUT 1'b1 - MAIN_PLL0_HSDIV8_CLKOUT
0x81B0 CFG0_WKUP_TIMER0_CLKSEL
  [2:0] WKUP_TIMER0_CLKSEL_CLK_SEL — Timer functional clock input select mux control Field values (others are reserved): 3'b000 - HFOSC0_CLKOUT 3'b001 - DM_CLK/2 undefined - undefined 3'b010 - CLK_12M_RC 3'b011 - MCU_PLL0_HSDIV3_CLKOUT 3'b100 - MCU_EXT_REFCLK0 (pin) 3'b101 - DEVICE_CLKOUT_32K 3'b110 - CPSW2G_CPTS_RFT_CLK 3'b111 - CLK_32K_RC
0x81B4 CFG0_WKUP_TIMER1_CLKSEL
  [2:0] WKUP_TIMER1_CLKSEL_CLK_SEL — Timer functional clock input select mux control Field values (others are reserved): 3'b000 - HFOSC0_CLKOUT 3'b001 - DM_CLK/2 undefined - undefined 3'b010 - CLK_12M_RC 3'b011 - MCU_PLL0_HSDIV3_CLKOUT 3'b100 - MCU_EXT_REFCLK0 (pin) 3'b101 - DEVICE_CLKOUT_32K 3'b110 - CPSW2G_CPTS_RFT_CLK 3'b111 - CLK_32K_RC
0x8340 CFG0_WKUP_WWD0_CTRL
  [3:0] WKUP_WWD0_CTRL_WWD_STOP — Controls Clocks to the WWD Watchdog Counter Field values (others are reserved): 4'b0000 - WWD Counter Running 4'b1010 - WWD Counter Stopped
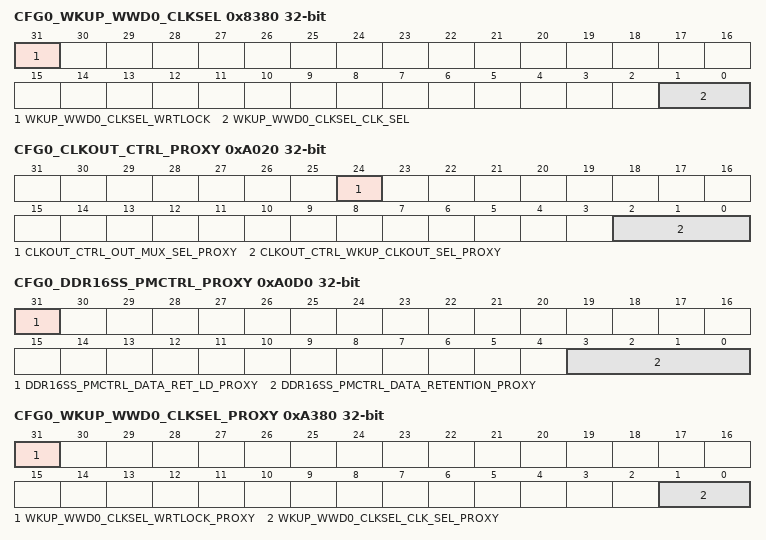
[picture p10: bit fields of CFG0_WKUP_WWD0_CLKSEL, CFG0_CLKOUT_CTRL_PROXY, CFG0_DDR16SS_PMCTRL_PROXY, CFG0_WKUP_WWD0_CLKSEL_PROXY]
0x8380 CFG0_WKUP_WWD0_CLKSEL
  [31] WKUP_WWD0_CLKSEL_WRTLOCK — When set, locks WWD0_CLKSEL from further writes until the next module reset.
  [1:0] WKUP_WWD0_CLKSEL_CLK_SEL — Windowed watchdog timer functional clock input select mux control Field values (others are reserved): 2'b00 - HFOSC0_CLKOUT 2'b01 - DEVICE_CLKOUT_32K 2'b10 - CLK_12M_RC 2'b11 - CLK_32K
0x8600 CFG0_WKUP_RTC_CLKSEL
  [0] WKUP_RTC_CLKSEL_CLK_SEL — Selects the source of the RTC functional clock Field values (others are reserved): 1'b0 - DEVICE_CLKOUT_32K 1'b1 - CLK_32K_RC
{0x9100+4i} CFG0_CLAIMREG_P2_R{i}_READONLY ro (i=0..12)
  [31:0] CLAIMREG_P2_R{i}_READONLY — Claim bits for Partition 2
0xA010 CFG0_WKUP_CLKSEL_PROXY
  [0] WKUP_CLKSEL_CLK_SEL_PROXY — Selects Clock Source for Wakeup Domain (Device Manager and Peripherals) Field values (others are reserved): 1'b0 - CPU: MAIN_PLL15_HSDIV2_CLKOUT, Peripherals: MAIN_PLL15_HSDIV0_CLKOUT0 1'b1 - CPU and Peripherals: MCU_PLL0_HSDIV0_CKLOUT
0xA020 CFG0_CLKOUT_CTRL_PROXY
  [24] CLKOUT_CTRL_OUT_MUX_SEL_PROXY — WKUP CLKOUT pin output mux selection. Note, when HFOSC0_CLK is selected (1'b1) the CLKOUT_CTRL_wkup_clkout_sel field must be programmed to 4'b0001. 1'b0 - The output of the WKUP CLKOUT output divider is output on the pin 1'b1 - HFOSC0_CLK is output on the pin
  [2:0] CLKOUT_CTRL_WKUP_CLKOUT_SEL_PROXY — Controls WKUP CLKOUT MUX for WKUP_CLKOUT0 Pin Field values (others are reserved): undefined - undefined 3'b000 - HFOSC0_CLKOUT 3'b001 - LFOSC0_CLKOUT 3'b010 - MAIN_PLL0_HSDIV2_CLKOUT 3'b011 - MAIN_PLL1_HSDIV2_CLKOUT 3'b100 - MAIN_PLL2_HSDIV9_CLKOUT 3'b101 - DEVICE_CLKOUT_32K 3'b110 - CLK_12M_RC 3'b111 - HFOSC0_CLKOUT
0xA030 CFG0_WKUP_GTC_CLKSEL_PROXY reset 0x1
  [2:0] WKUP_GTC_CLKSEL_CLK_SEL_PROXY — Selects the GTC timebase clock source Field values (others are reserved): 3'b000 - MAIN_PLL2_HSDIV5_CLKOUT 3'b001 - MAIN_PLL0_HSDIV6_CLKOUT 3'b010 - CPSW2G_CPTS_RFT_CLK 3'b011 - Reserved '0' 3'b100 - MCU_EXT_REFCLK0 3'b101 - EXT_REFCLK1 3'b110 - MCU_SYSCLK0 undefined - undefined 3'b111 - MAIN_SYSCLK0
0xA03C CFG0_EFUSE_CLKSEL_PROXY
  [0] EFUSE_CLKSEL_CLK_SEL_PROXY — Selects the clock source Field values (others are reserved): 1'b0 - HFOSC0_CLKOUT 1'b1 - MAIN_SYSCLK0/16
0xA0D0 CFG0_DDR16SS_PMCTRL_PROXY
  [31] DDR16SS_PMCTRL_DATA_RET_LD_PROXY — Controls latching of the retention value Field values (others are reserved): 1'b0 - Latch Closed 1'b1 - Latch Open
  [3:0] DDR16SS_PMCTRL_DATA_RETENTION_PROXY — DDR16SS Retention: This is a fault tolerant bit field 0x06 Asserts DDRSS 'data_retention' which will Hi-Z most of the phy output pins except for CKE/RESET# All others (Default 0) : data_retention is deasserted for normal DDR16SS Operation Field values (others are reserved): 4'b0110 - Retention Activated 4'b0000 - Retention Deactivated
0xA190 CFG0_USB0_CLKSEL_PROXY
  [0] USB0_CLKSEL_REFCLK_SEL_PROXY — Selects the clock source for the USB0 ref_clk. Field values (others are reserved): 1'b0 - HFOSC0_CLKOUT 1'b1 - MAIN_PLL0_HSDIV8_CLKOUT
0xA194 CFG0_USB1_CLKSEL_PROXY
  [0] USB1_CLKSEL_REFCLK_SEL_PROXY — Selects the clock source for the USB1 ref_clk. Field values (others are reserved): 1'b0 - HFOSC0_CLKOUT 1'b1 - MAIN_PLL0_HSDIV8_CLKOUT
0xA1B0 CFG0_WKUP_TIMER0_CLKSEL_PROXY
  [2:0] WKUP_TIMER0_CLKSEL_CLK_SEL_PROXY — Timer functional clock input select mux control Field values (others are reserved): 3'b000 - HFOSC0_CLKOUT 3'b001 - DM_CLK/2 undefined - undefined 3'b010 - CLK_12M_RC 3'b011 - MCU_PLL0_HSDIV3_CLKOUT 3'b100 - MCU_EXT_REFCLK0 (pin) 3'b101 - DEVICE_CLKOUT_32K 3'b110 - CPSW2G_CPTS_RFT_CLK 3'b111 - CLK_32K_RC
0xA1B4 CFG0_WKUP_TIMER1_CLKSEL_PROXY
  [2:0] WKUP_TIMER1_CLKSEL_CLK_SEL_PROXY — Timer functional clock input select mux control Field values (others are reserved): 3'b000 - HFOSC0_CLKOUT 3'b001 - DM_CLK/2 undefined - undefined 3'b010 - CLK_12M_RC 3'b011 - MCU_PLL0_HSDIV3_CLKOUT 3'b100 - MCU_EXT_REFCLK0 (pin) 3'b101 - DEVICE_CLKOUT_32K 3'b110 - CPSW2G_CPTS_RFT_CLK 3'b111 - CLK_32K_RC
0xA340 CFG0_WKUP_WWD0_CTRL_PROXY
  [3:0] WKUP_WWD0_CTRL_WWD_STOP_PROXY — Controls Clocks to the WWD Watchdog Counter Field values (others are reserved): 4'b0000 - WWD Counter Running 4'b1010 - WWD Counter Stopped
0xA380 CFG0_WKUP_WWD0_CLKSEL_PROXY
  [31] WKUP_WWD0_CLKSEL_WRTLOCK_PROXY — When set, locks WWD0_CLKSEL from further writes until the next module reset.
  [1:0] WKUP_WWD0_CLKSEL_CLK_SEL_PROXY — Windowed watchdog timer functional clock input select mux control Field values (others are reserved): 2'b00 - HFOSC0_CLKOUT 2'b01 - DEVICE_CLKOUT_32K 2'b10 - CLK_12M_RC 2'b11 - CLK_32K
0xA600 CFG0_WKUP_RTC_CLKSEL_PROXY
  [0] WKUP_RTC_CLKSEL_CLK_SEL_PROXY — Selects the source of the RTC functional clock Field values (others are reserved): 1'b0 - DEVICE_CLKOUT_32K 1'b1 - CLK_32K_RC
{0xB100+4i} CFG0_CLAIMREG_P2_R{i} (i=0..12)
  [31:0] CLAIMREG_P2_R{i} — Claim bits for Partition 2
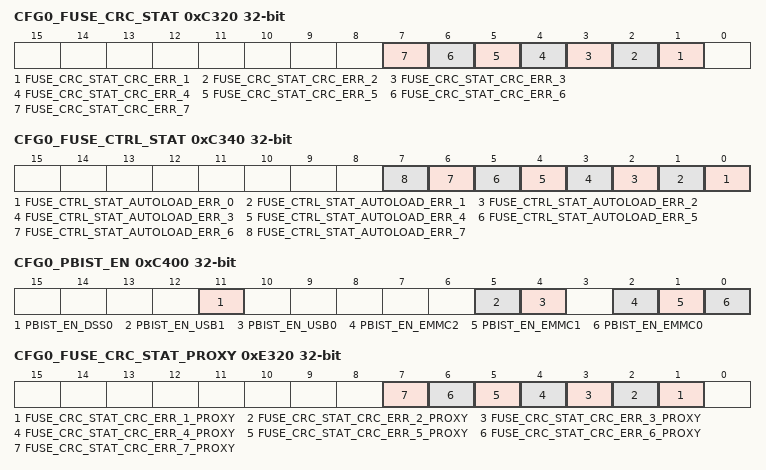
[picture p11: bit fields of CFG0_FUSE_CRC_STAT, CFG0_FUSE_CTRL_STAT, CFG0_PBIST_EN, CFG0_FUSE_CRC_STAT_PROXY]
0xC320 CFG0_FUSE_CRC_STAT ro
  [n] FUSE_CRC_STAT_CRC_ERR_{n} (n=1..7) — Indicates eFuse CRC error on chain {n}
0xC340 CFG0_FUSE_CTRL_STAT ro
  [n] FUSE_CTRL_STAT_AUTOLOAD_ERR_{n} (n=0..7) — Autoload Error Status Chain {n}
0xC400 CFG0_PBIST_EN
  [11] PBIST_EN_DSS0 — Activates PBIST Access to DSS0 Memories
  [5] PBIST_EN_USB1 — Activates PBIST Access to USB1 Memories
  [4] PBIST_EN_USB0 — Activates PBIST Access to USB0 Memories
  [2] PBIST_EN_EMMC2 — Activates PBIST Access to MMC2 Memories
  [1] PBIST_EN_EMMC1 — Activates PBIST Access to MMC1 Memories
  [0] PBIST_EN_EMMC0 — Activates PBIST Access to MMC0 Memories
{0xD100+4i} CFG0_CLAIMREG_P3_R{i}_READONLY ro (i=0..8)
  [31:0] CLAIMREG_P3_R{i}_READONLY — Claim bits for Partition 3
0xE320 CFG0_FUSE_CRC_STAT_PROXY ro
  [n] FUSE_CRC_STAT_CRC_ERR_{n}_PROXY (n=1..7) — Indicates eFuse CRC error on chain {n}
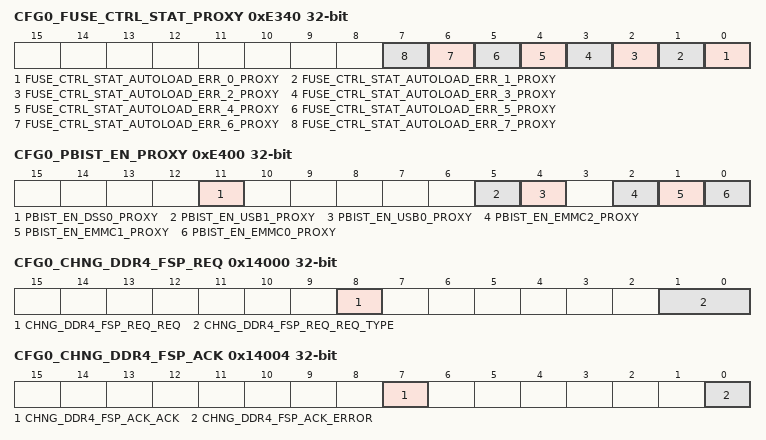
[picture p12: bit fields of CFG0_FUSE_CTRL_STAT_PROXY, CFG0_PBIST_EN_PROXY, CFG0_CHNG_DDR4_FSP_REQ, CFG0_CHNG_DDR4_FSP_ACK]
0xE340 CFG0_FUSE_CTRL_STAT_PROXY ro
  [n] FUSE_CTRL_STAT_AUTOLOAD_ERR_{n}_PROXY (n=0..7) — Autoload Error Status Chain {n}
0xE400 CFG0_PBIST_EN_PROXY
  [11] PBIST_EN_DSS0_PROXY — Activates PBIST Access to DSS0 Memories
  [5] PBIST_EN_USB1_PROXY — Activates PBIST Access to USB1 Memories
  [4] PBIST_EN_USB0_PROXY — Activates PBIST Access to USB0 Memories
  [2] PBIST_EN_EMMC2_PROXY — Activates PBIST Access to MMC2 Memories
  [1] PBIST_EN_EMMC1_PROXY — Activates PBIST Access to MMC1 Memories
  [0] PBIST_EN_EMMC0_PROXY — Activates PBIST Access to MMC0 Memories
{0xF100+4i} CFG0_CLAIMREG_P3_R{i} (i=0..8)
  [31:0] CLAIMREG_P3_R{i} — Claim bits for Partition 3
{0x11100+4i} CFG0_CLAIMREG_P4_R{i}_READONLY ro (i=0..8)
  [31:0] CLAIMREG_P4_R{i}_READONLY — Claim bits for Partition 4
{0x13100+4i} CFG0_CLAIMREG_P4_R{i} (i=0..8)
  [31:0] CLAIMREG_P4_R{i} — Claim bits for Partition 4
0x14000 CFG0_CHNG_DDR4_FSP_REQ
  [8] CHNG_DDR4_FSP_REQ_REQ — Initiate FSP frequency change
  [1:0] CHNG_DDR4_FSP_REQ_REQ_TYPE — Frequency request type Indicates which DDR4 frequency set point to change to
0x14004 CFG0_CHNG_DDR4_FSP_ACK ro
  [7] CHNG_DDR4_FSP_ACK_ACK — Frequency change acknowledge. This bit is only valid when CHNG_DDR4_FSP_REQ_req = 1 Indication from the DDR Controller that the FSP change operation is complete 0 - FSP change operation in progress 1 - FSP change operation complete
  [0] CHNG_DDR4_FSP_ACK_ERROR — Frequency change error This bit is only valid when CHNG_DDR4_FSP_REQ_req = 1 0 - FSP change was sucessful 1 - FSP change was not sucessful
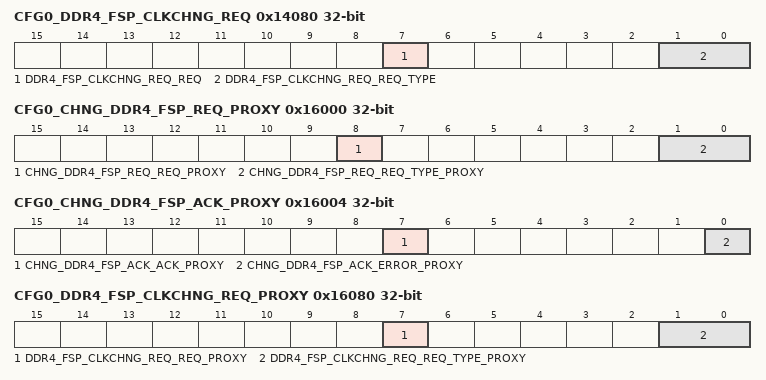
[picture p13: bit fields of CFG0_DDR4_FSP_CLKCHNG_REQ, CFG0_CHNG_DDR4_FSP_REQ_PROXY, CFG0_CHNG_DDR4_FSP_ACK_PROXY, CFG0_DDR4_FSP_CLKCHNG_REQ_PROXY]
0x14080 CFG0_DDR4_FSP_CLKCHNG_REQ ro
  [7] DDR4_FSP_CLKCHNG_REQ_REQ — DDR Controller FSP clock change request Indicates that the DDR controller needs the DDR clock changed to the frequency indicated by the req_type field. This bit is cleared when the DDR4_FSP_CLKCHNG_ACK_ack bit is set.
  [1:0] DDR4_FSP_CLKCHNG_REQ_REQ_TYPE — Frequency request type Indicates which DDR4 FSP frequency to which the DDR Controller wants the DDR clock set
0x140C0 CFG0_DDR4_FSP_CLKCHNG_ACK
  [0] DDR4_FSP_CLKCHNG_ACK_ACK — DDR FSP clock change ackowledge This bit should be set once the DDR clock has been sucessfully changed to the value requested by DDR4_FSP_CLKCHNG_REQ_req_type. Setting this bit will clear the DDR4_FSP_CLKCHNG_REQ_req bit and the associated change request interrupt.
0x15100 CFG0_CLAIMREG_P5_R0_READONLY ro
  [31:0] CLAIMREG_P5_R0_READONLY — Claim bits for Partition 5
0x15104 CFG0_CLAIMREG_P5_R1_READONLY ro
  [31:0] CLAIMREG_P5_R1_READONLY — Claim bits for Partition 5
0x16000 CFG0_CHNG_DDR4_FSP_REQ_PROXY
  [8] CHNG_DDR4_FSP_REQ_REQ_PROXY — Initiate FSP frequency change
  [1:0] CHNG_DDR4_FSP_REQ_REQ_TYPE_PROXY — Frequency request type Indicates which DDR4 frequency set point to change to
0x16004 CFG0_CHNG_DDR4_FSP_ACK_PROXY ro
  [7] CHNG_DDR4_FSP_ACK_ACK_PROXY — Frequency change acknowledge. This bit is only valid when CHNG_DDR4_FSP_REQ_req = 1 Indication from the DDR Controller that the FSP change operation is complete 0 - FSP change operation in progress 1 - FSP change operation complete
  [0] CHNG_DDR4_FSP_ACK_ERROR_PROXY — Frequency change error This bit is only valid when CHNG_DDR4_FSP_REQ_req = 1 0 - FSP change was sucessful 1 - FSP change was not sucessful
0x16080 CFG0_DDR4_FSP_CLKCHNG_REQ_PROXY ro
  [7] DDR4_FSP_CLKCHNG_REQ_REQ_PROXY — DDR Controller FSP clock change request Indicates that the DDR controller needs the DDR clock changed to the frequency indicated by the req_type field. This bit is cleared when the DDR4_FSP_CLKCHNG_ACK_ack bit is set.
  [1:0] DDR4_FSP_CLKCHNG_REQ_REQ_TYPE_PROXY — Frequency request type Indicates which DDR4 FSP frequency to which the DDR Controller wants the DDR clock set
0x160C0 CFG0_DDR4_FSP_CLKCHNG_ACK_PROXY
  [0] DDR4_FSP_CLKCHNG_ACK_ACK_PROXY — DDR FSP clock change ackowledge This bit should be set once the DDR clock has been sucessfully changed to the value requested by DDR4_FSP_CLKCHNG_REQ_req_type. Setting this bit will clear the DDR4_FSP_CLKCHNG_REQ_req bit and the associated change request interrupt.
0x17100 CFG0_CLAIMREG_P5_R0
  [31:0] CLAIMREG_P5_R0 — Claim bits for Partition 5
0x17104 CFG0_CLAIMREG_P5_R1
  [31:0] CLAIMREG_P5_R1 — Claim bits for Partition 5
0x18040 CFG0_FW_CTRL_OUT0
  [31:0] FW_CTRL_OUT0_FW_CTRL_OUT0
0x18044 CFG0_FW_CTRL_OUT0_SET access not given reset not defined
0x18048 CFG0_FW_CTRL_OUT0_CLR access not given reset not defined
0x1804C CFG0_FW_STS_IN0 access not given reset not defined
0x18050 CFG0_FW_CTRL_OUT1 access not given reset not defined
0x18054 CFG0_FW_CTRL_OUT1_SET access not given reset not defined
0x18058 CFG0_FW_CTRL_OUT1_CLR access not given reset not defined
0x1805C CFG0_FW_STS_IN1 access not given reset not defined
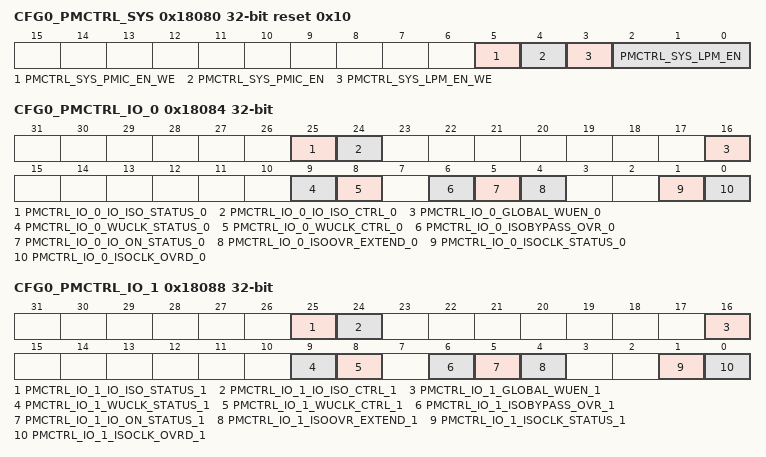
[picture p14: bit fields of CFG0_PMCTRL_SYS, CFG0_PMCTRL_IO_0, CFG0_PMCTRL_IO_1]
0x18080 CFG0_PMCTRL_SYS reset 0x10
  [5] PMCTRL_SYS_PMIC_EN_WE — Unused Field - Value is Don't Care
  [4] PMCTRL_SYS_PMIC_EN — Controls state of PMIC_LPM_EN_OUT when LPM_EN[2:0] is 000
  [3] PMCTRL_SYS_LPM_EN_WE — Unused Field - Value is Don't Care
  [2:0] PMCTRL_SYS_LPM_EN — Controls whether PMIC_LPM_EN_OUT is driven by the pmic_en bit, or by deep sleep logic. Field values (others are reserved): 3'b000 - PMIC_LPM_EN_OUT controlled by pmic_en bit. 3'b101 - PMIC_LPM_EN_OUT controlled by DeepSleep Logic
0x18084 CFG0_PMCTRL_IO_0 access per field
  [25] PMCTRL_IO_0_IO_ISO_STATUS_0 ro — IO ISO Status. Read 0: IO isolation not active. Read 1: IO isolation active. Reflects value of DM input port io_isoack coming back from IO pad ring.
  [24] PMCTRL_IO_0_IO_ISO_CTRL_0 rw — IO ISO control. Writing this bit to 1 will kick off IO isolation.
  [16] PMCTRL_IO_0_GLOBAL_WUEN_0 rw — Global IO wakeup activate. This is a gating condition to all individual IO WUEN coming from control module. Gating is done in the Spinner logic. 0:All individual IO WUEN are gated in the Spinner logic (override to 0). 1: All individual IO WUEN from control module are going to Ios. Map to DM input port io_globalwkupen
  [9] PMCTRL_IO_0_WUCLK_STATUS_0 ro — Reflects value of DM input port io_wuclkack coming back from IO pad ring.
  [8] PMCTRL_IO_0_WUCLK_CTRL_0 rw — Direct control on WUCLKIN signal to IO pad ring.0:WUCLKIN signal is driven to 0.IO wakeup daisy chain is functional as well as IO whose wakeup feature is activated. 1:WUCLKIN signal is driven to 1. IO wakeup daisy chain is reset and is latching current pad states and WUEN inputs.
  [6] PMCTRL_IO_0_ISOBYPASS_OVR_0 rw — This MMR bit drives directly DM output port io_isobypassundefined.
  [5] PMCTRL_IO_0_IO_ON_STATUS_0 ro — Gives the functional status of the IO ring. Read 0: Part or all of the Ios are not in the ON state that is are in isolation state. Read 1: All Ios are in the ON state. io_on_status = assign 1 if (io_iso == 0 & io_isoack==0 & io_iso_clk == 0 & io_isoclk_ack = 0 ) else 0;
  [4] PMCTRL_IO_0_ISOOVR_EXTEND_0 rw — This drives the SOC chain ISO-OVERRIDE global control. This bit drives directly the DM output port io_isoovrundefined. At the SOC level it is used to activate when 1 or gate-off when 0, the individual ISOOR for each IO. This operates as a global activate/deactivate for the individual IOs.Control for IO isolation extension. '0' IO isolation is not extended. Transition happens as soon as automatic restore is completed. '1' IO isolation is extended. The IOs whose ISOOVR bits have been individually set in their PADCFG MMRs will all get its IO isolation extended beyond the point when the initial IO daisy chain isolation is released.
  [1] PMCTRL_IO_0_ISOCLK_STATUS_0 ro — Reflects value of DM input port io_isoclkack coming back from IO pad ring.
  [0] PMCTRL_IO_0_ISOCLK_OVRD_0 rw — Override control on ISOCLKIN signal to IO pad ring. When not overridden this signal is controlled by hardware only. 0 ISOCLKIN signal is not override. 1 ISOCLKIN signal is overridden to active value ('1').
0x18088 CFG0_PMCTRL_IO_1 access per field
  [25] PMCTRL_IO_1_IO_ISO_STATUS_1 ro — IO ISO Status. Read 0: IO isolation not active. Read 1: IO isolation active. Reflects value of DM input port io_isoack coming back from IO pad ring.
  [24] PMCTRL_IO_1_IO_ISO_CTRL_1 rw — IO ISO control. Writing this bit to 1 will kick off IO isolation.
  [16] PMCTRL_IO_1_GLOBAL_WUEN_1 rw — Global IO wakeup activate. This is a gating condition to all individual IO WUEN coming from control module. Gating is done in the Spinner logic. 0:All individual IO WUEN are gated in the Spinner logic (override to 0). 1: All individual IO WUEN from control module are going to Ios. Map to DM input port io_globalwkupen
  [9] PMCTRL_IO_1_WUCLK_STATUS_1 ro — Reflects value of DM input port io_wuclkack coming back from IO pad ring.
  [8] PMCTRL_IO_1_WUCLK_CTRL_1 rw — Direct control on WUCLKIN signal to IO pad ring.0:WUCLKIN signal is driven to 0.IO wakeup daisy chain is functional as well as IO whose wakeup feature is activated. 1:WUCLKIN signal is driven to 1. IO wakeup daisy chain is reset and is latching current pad states and WUEN inputs.
  [6] PMCTRL_IO_1_ISOBYPASS_OVR_1 rw — This MMR bit drives directly DM output port io_isobypassundefined.
  [5] PMCTRL_IO_1_IO_ON_STATUS_1 ro — Gives the functional status of the IO ring. Read 0: Part or all of the Ios are not in the ON state that is are in isolation state. Read 1: All Ios are in the ON state. io_on_status = assign 1 if (io_iso == 0 & io_isoack==0 & io_iso_clk == 0 & io_isoclk_ack = 0 ) else 0;
  [4] PMCTRL_IO_1_ISOOVR_EXTEND_1 rw — This drives the SOC chain ISO-OVERRIDE global control. This bit drives directly the DM output port io_isoovrundefined. At the SOC level it is used to activate when 1 or gate-off when 0, the individual ISOOR for each IO. This operates as a global activate/deactivate for the individual IOs.Control for IO isolation extension. '0' IO isolation is not extended. Transition happens as soon as automatic restore is completed. '1' IO isolation is extended. The IOs whose ISOOVR bits have been individually set in their PADCFG MMRs will all get its IO isolation extended beyond the point when the initial IO daisy chain isolation is released.
  [1] PMCTRL_IO_1_ISOCLK_STATUS_1 ro — Reflects value of DM input port io_isoclkack coming back from IO pad ring.
  [0] PMCTRL_IO_1_ISOCLK_OVRD_1 rw — Override control on ISOCLKIN signal to IO pad ring. When not overridden this signal is controlled by hardware only. 0 ISOCLKIN signal is not override. 1 ISOCLKIN signal is overridden to active value ('1').
